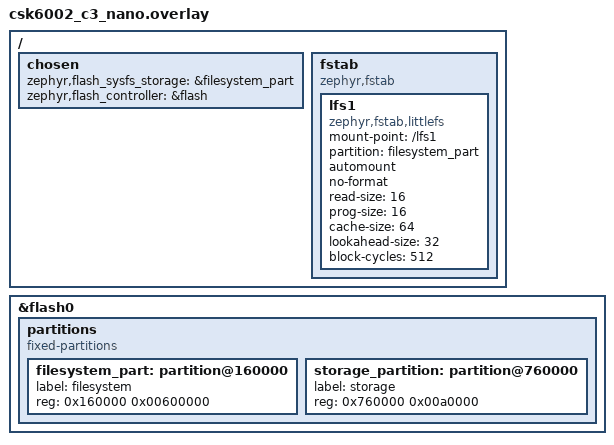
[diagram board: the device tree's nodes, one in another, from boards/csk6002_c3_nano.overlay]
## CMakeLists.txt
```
cmake_minimum_required(VERSION 3.20.0)
# Copyright (c) 2018 Nordic Semiconductor ASA
# Copyright (c) 2019 Linaro Limited
#
# SPDX-License-Identifier: Apache-2.0
#

if("${BOARD}" STREQUAL "csk6002_c3_nano")
  set(BUILD_DSP_FIRMWARE ON)
  find_package(Zephyr REQUIRED HINTS $ENV{ZEPHYR_BASE})
  message(INFO " ${BOARD} compile as Master in this sample")
  target_sources(app PRIVATE src/main.c)
  add_subdirectory(./src)

else("${BOARD}" STREQUAL "ls_adsp_csk6")
  set(BUILD_DSP_FIRMWARE ON)
endif()


if(BUILD_DSP_FIRMWARE)

  set(REMOTE_ZEPHYR_DIR ${CMAKE_CURRENT_BINARY_DIR}/openamp_remote-prefix/src/openamp_remote-build/zephyr)

  if("${BOARD}" STREQUAL "csk6002_c3_nano")
    set(BOARD_REMOTE "ls_adsp_csk6")
  else()
    message(FATAL_ERROR "${BOARD} was not supported for this sample")
  endif()

  project(openamp)

  enable_language(C ASM)

  #target_sources(app PRIVATE src/load_fw.c src/mem_image_store.c src/platform_info.c src/zynqmp_csk6001_rproc_example.c )

  include(ExternalProject)

  set(ENV{XCC_USE_CLANG} "1")
  set(ENV{ZEPHYR_TOOLCHAIN_VARIANT} "xcc")

  ExternalProject_Add(
    openamp_remote
    SOURCE_DIR ${APPLICATION_SOURCE_DIR}/remote
    INSTALL_COMMAND ""      # This particular build system has no install command
    CMAKE_CACHE_ARGS -DBOARD:STRING=${BOARD_REMOTE}
    BUILD_BYPRODUCTS "${REMOTE_ZEPHYR_DIR}/${KERNEL_BIN_NAME}"
    # NB: Do we need to pass on more CMake variables?
    BUILD_ALWAYS True
  )

  unset(ENV{XCC_USE_CLANG})
  unset(ENV{ZEPHYR_TOOLCHAIN_VARIANT})
  # target_include_directories(app PRIVATE ${CMAKE_CURRENT_SOURCE_DIR} ./src) 

endif()

target_include_directories(app PRIVATE ${CMAKE_CURRENT_SOURCE_DIR} ./src) 
```

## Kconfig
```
# Private config options for load sencond core firmware app

# SPDX-License-Identifier: Apache-2.0

# Workaround for not being able to have commas in macro arguments

menu "Load Second Core Options"
	depends on SOC_CSK6001

choice
	prompt "The second core load method selection"
	default SECOND_CORE_LOAD_BY_LITTLEFS

config SECOND_CORE_LOAD_BY_FLASH_ELF
	bool "load the second core fw by *.elf file store at flash area"

config SECOND_CORE_IMAGE_ELF_ADDR
	depends on SECOND_CORE_LOAD_BY_FLASH_ELF
	hex "Address the second core firmware storage in flash,the file must be elf format"
	default 0x18200000
	help
	  This is the address the second core image storage in flash. Additionally
	  The data at this address will be load to run at the boot address.

config SECOND_CORE_LOAD_BY_FLASH_BINARY
	bool "load the second core fw by *.bin file store at flash area"

config SECOND_CORE_IMAGE_BINARY_ADDR
	depends on SECOND_CORE_LOAD_BY_FLASH_BINARY
	hex "Address the second core firmware storage in flash,the file must be binary format"
	default 0x18200000
	help
	  This is the address the second core image storage in flash. Additionally
	  The data at this address will be load to run at the boot address.

config SECOND_CORE_IMAGE_BINARY_SIZE
	depends on SECOND_CORE_LOAD_BY_FLASH_BINARY
	hex "The binary fw size of second core firmware storage in flash,the file must be binary format"
	default 0x100000
	help
	  This is the address the second core image storage in flash. Additionally
	  The data at this address will be load to run at the boot address.

config SECOND_CORE_LOAD_BY_LITTLEFS
	bool "load the second core fw by littleFS"
	imply DISK_DRIVER_FLASH
	imply FILE_SYSTEM
	imply FILE_SYSTEM_LITTLEFS

config SECOND_CORE_IMAGE_NAME
	depends on SECOND_CORE_LOAD_BY_LITTLEFS
	default "zephyr.bin"
	string "Binary image name of second core's code"
	help
	  This points to the image file for the the binary code that will be
	  used by the second core.


config SECOND_CORE_LOAD_BY_FATFS
	bool "load the second core fw by fatfs"
	imply DISK_DRIVER_FLASH
	imply FILE_SYSTEM
	imply FAT_FILESYSTEM_ELM


config SECOND_CORE_IMAGE_NAME
	depends on SECOND_CORE_LOAD_BY_FATFS
	default "zephyr.bin"
	string "Binary image name of second core's code"
	help
	  This points to the image file for the the binary code that will be
	  used by the second core.

endchoice


config SECOND_CORE_BOOT_ADDRESS
	hex "Address the second core will boot at"
	default 0x60000000
	help
	  This is the address the second core will boot from. Additionally this
	  address is where we will copy the SECOND_IMAGE to. We default this to
	  the base of PSRAM.


endmenu

if DISK_DRIVER_FLASH

DT_CHOSEN_Z_FLASH_SYSFS_STORAGE := zephyr,flash_sysfs_storage
DT_CHOSEN_Z_FLASH_CONTROLLER := zephyr,flash_controller
DT_CHOSEN_Z_INN_FLASH := zephyr,flash


config DISK_FLASH_START
	default "$(dt_chosen_reg_addr_hex,$(DT_CHOSEN_Z_FLASH_SYSFS_STORAGE))"

config DISK_FLASH_DEV_NAME
	default "$(dt_chosen_label,$(DT_CHOSEN_Z_FLASH_CONTROLLER))"

config DISK_VOLUME_SIZE
	default "$(dt_chosen_reg_size_hex,$(DT_CHOSEN_Z_FLASH_SYSFS_STORAGE))"


config DISK_FLASH_MAX_RW_SIZE
	default 4096
	#default $(dt_node_int_prop_hex,$(DT_CHOSEN_Z_INN_FLASH),erase-block-size)

config DISK_FLASH_ERASE_ALIGNMENT
	default 0x1000
	#default "$(dt_node_int_prop_hex,$(DT_CHOSEN_Z_INN_FLASH),erase-block-size)"

config DISK_ERASE_BLOCK_SIZE
	default 0x1000
	#default "$(dt_node_int_prop_hex,$(DT_CHOSEN_Z_INN_FLASH),erase-block-size)"

#USB config
config MASS_STORAGE_DISK_NAME
	default "NAND" 


config FLASH_LOG_LEVEL
	default 4


		
endif #DISK_DRIVER_FLASH

config FLASH
	default y

config FLASH_MAP
	default y

config FLASH_PAGE_LAYOUT
	default y

source "Kconfig.zephyr"
```

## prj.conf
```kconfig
CONFIG_PRINTK=y
CONFIG_DEBUG=y
CONFIG_LOG=y
CONFIG_MAIN_STACK_SIZE=4096
CONFIG_HEAP_MEM_POOL_SIZE=8192

#openamp config
CONFIG_OPENAMP=y
CONFIG_OPENAMP_SLAVE=n
CONFIG_CACHE_MANAGEMENT=y
CONFIG_HAS_EXTERNAL_CACHE=y

#psram init 
CONFIG_MINIMAL_LIBC_RAND=y

#file system select
#CONFIG_SECOND_CORE_LOAD_BY_LITTLEFS=y
CONFIG_SECOND_CORE_LOAD_BY_FATFS=y
#CONFIG_SECOND_CORE_LOAD_BY_FLASH_ELF=y
#CONFIG_SECOND_CORE_LOAD_BY_FLASH_BINARY=y


#usb mass storage
CONFIG_USB_DEVICE_STACK=y
CONFIG_USB_DEVICE_PRODUCT="Zephyr DFU sample"
CONFIG_USB_MASS_STORAGE=y
CONFIG_MASS_STORAGE_STACK_SIZE=4096
CONFIG_SYSTEM_WORKQUEUE_STACK_SIZE=4096


CONFIG_USB_DRIVER_LOG_LEVEL_ERR=y
CONFIG_USB_DEVICE_LOG_LEVEL_ERR=y
CONFIG_USB_MASS_STORAGE_LOG_LEVEL_ERR=y
CONFIG_USB_DRIVER_LOG_LEVEL_ERR=y



#usb dfu
# CONFIG_USB_DFU_CLASS=y
# CONFIG_IMG_MANAGER=y
# CONFIG_IMG_BLOCK_BUF_SIZE=4096
# CONFIG_BOOTLOADER_MCUBOOT=y

#Fixd for WinUSB driver install.
CONFIG_USB_DEVICE_VID=0x2FE3
CONFIG_USB_DEVICE_PID=0x200
```

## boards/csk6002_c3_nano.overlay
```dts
/*
 * Copyright (c) 2021 listenai Intelligent Technology (anhui) Co., Ltd.
 *
 * SPDX-License-Identifier: Apache-2.0
 */
/delete-node/ &storage_partition;

/ {
	chosen {
		/*
		 * shared memory reserved for the inter-processor communication
		 */
		zephyr,flash_sysfs_storage = &filesystem_part;
		zephyr,flash_controller = &flash;
	};
	
	fstab {
		compatible = "zephyr,fstab";
		lfs1: lfs1 {
			compatible = "zephyr,fstab,littlefs";
			mount-point = "/lfs1";
			partition = <&filesystem_part>;
			automount ;
			no-format;
			read-size = <16>;
			prog-size = <16>;
			cache-size = <64>;
			lookahead-size = <32>;
			block-cycles = <512>;
		};
	};

};

 
&flash0 {
	partitions {
		compatible = "fixed-partitions";
		#address-cells = <1>;
		#size-cells = <1>;
		filesystem_part: partition@160000 {
			label = "filesystem";
			reg = <0x160000 0x00600000>;
		};
		/*
		 * Reserve the final 640 KiB for file system partition
		 */
		storage_partition: partition@760000 {
			label = "storage";
			reg = <0x760000 0x00a0000>;
		};
	};
};
```

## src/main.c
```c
/*
 *
 * SPDX-License-Identifier: Apache-2.0
 */

#include <zephyr.h>
#include <device.h>
#include <fs/fs.h>
#if defined(CONFIG_SECOND_CORE_LOAD_BY_LITTLEFS)
#include <fs/littlefs.h>
#include <storage/flash_map.h>
#include <usb/usb_device.h>
#elif defined(CONFIG_SECOND_CORE_LOAD_BY_FATFS)
#include <ff.h>
#include <usb/usb_device.h>
#endif

#include <drivers/ipm.h>
#include <sys/printk.h>
#include <stdio.h>
#include <stdlib.h>
#include <string.h>
#include <init.h>

#include <openamp/open_amp.h>
#include <metal/device.h>
#include <remote_core_ctrl.h>
#include <hal/PSRAMManager.h>
#include <hal/ClockManager.h>
#include <hal/SysManager.h>

#if defined(CONFIG_SECOND_CORE_LOAD_BY_LITTLEFS) || defined(CONFIG_SECOND_CORE_LOAD_BY_FATFS)

#if defined(CONFIG_SECOND_CORE_LOAD_BY_LITTLEFS)
/* Matches LFS_NAME_MAX */
#define MAX_PATH_LEN 255
#define PARTITION_NODE DT_NODELABEL(lfs1)
#if DT_NODE_EXISTS(PARTITION_NODE)
FS_FSTAB_DECLARE_ENTRY(PARTITION_NODE);
struct fs_mount_t *p_g_fs_mount = &FS_FSTAB_ENTRY(PARTITION_NODE);
#else /* PARTITION_NODE */
#error "Please declare the region of the file system first"
#endif /* PARTITION_NODE */
#elif defined(CONFIG_SECOND_CORE_LOAD_BY_FATFS)
#define FS_MOUNT_POINT "/NAND:"
struct fs_mount_t *p_g_fs_mount = NULL;
static struct fs_mount_t s_fs_mount;
static FATFS s_fat_fs;

#endif

static void fssys_show(struct fs_mount_t *mp)
{
	struct fs_statvfs sbuf;
	int rc;

	rc = fs_statvfs(mp->mnt_point, &sbuf);
	if (rc < 0) {
		printk("FAIL: statvfs: %d\n", rc);
		goto out;
	}

	printk("%s: bsize = %lu ; frsize = %lu ;"
	       " blocks = %lu ; bfree = %lu\n",
	       mp->mnt_point, sbuf.f_bsize, sbuf.f_frsize, sbuf.f_blocks, sbuf.f_bfree);

	struct fs_dir_t dir;

	fs_dir_t_init(&dir);

	rc = fs_opendir(&dir, mp->mnt_point);
	printk("%s opendir: %d\n", mp->mnt_point, rc);

	while (rc >= 0) {
		struct fs_dirent ent = { 0 };

		rc = fs_readdir(&dir, &ent);
		if (rc < 0) {
			break;
		}
		if (ent.name[0] == 0) {
			printk("End of files\n");
			break;
		}
		printk("  %c %zu %s\n", (ent.type == FS_DIR_ENTRY_FILE) ? 'F' : 'D', ent.size,
		       ent.name);
	}

	(void)fs_closedir(&dir);
	printk("%s closedir\n", mp->mnt_point);
out:
	return;
}

static int fs_init(void)
{
	struct fs_mount_t *mp;

#if defined(CONFIG_SECOND_CORE_LOAD_BY_LITTLEFS)
	mp = p_g_fs_mount;
	/* Do not mount if auto-mount has been enabled */
#if !DT_NODE_EXISTS(PARTITION_NODE) ||                                                             \
	!(FSTAB_ENTRY_DT_MOUNT_FLAGS(PARTITION_NODE) & FS_MOUNT_FLAG_AUTOMOUNT)

	int rc = fs_mount(mp);
	if (rc < 0) {
		printk("FAIL: mount id %" PRIuPTR " at %s: %d\n", (uintptr_t)mp->storage_dev,
		       mp->mnt_point, rc);
		return rc;
	}
	printk("%s mount: %d\n", mp->mnt_point, rc);
#else
	printk("%s automounted\n", mp->mnt_point);
#endif

#elif defined(CONFIG_SECOND_CORE_LOAD_BY_FATFS)
	if (p_g_fs_mount != NULL) {
		printk("The mount point<%s> busy!\n", p_g_fs_mount->mnt_point);
		return -1;
	}
	p_g_fs_mount = &s_fs_mount;
	mp = p_g_fs_mount;
	memset(mp, 0, sizeof(struct fs_mount_t));
	mp->type = FS_FATFS;
	mp->flags |= FS_MOUNT_FLAG_NO_FORMAT;
	mp->fs_data = &s_fat_fs;
	mp->mnt_point = FS_MOUNT_POINT;
	int rc = fs_mount(mp);
	if (rc < 0) {
		printk("FAIL: mount id %" PRIuPTR " at %s: %d\n", (uintptr_t)mp->storage_dev,
		       mp->mnt_point, rc);
		return rc;
	}
	printk("%s mount: %d\n", mp->mnt_point, rc);
#endif
	fssys_show(mp);

	return 0;
}
#endif

#if 0
void remote_runing_tester(int restartNumver)
{
	struct remoteproc *rproc = NULL;
	uint32_t testcnt = 0;
	uint32_t wait_ms = 0;
	int iret;

	rproc = remote_core_create(2);
	if (rproc == NULL) {
		LPRINTF("[%s %d]remote_core_create failed!\n", __FUNCTION__, __LINE__);
		return;
	}
	LPRINTF("Step1: Create rproc success!\n");

	iret = remote_core_loadFw(rproc);
	if (0 != iret) {
		LPRINTF("[%s %d]remote_core_loadFw failed!\n", __FUNCTION__, __LINE__);
		return;
	}
	LPRINTF("Step2: load second core firmware success!\n");

	for (testcnt = 0; testcnt < restartNumver; testcnt++) {
		LPRINTF("----tester loop cnt =%d---------\n", testcnt);
		if (testcnt > 0) {
			iret = remote_core_config(rproc, NULL);
			if (0 != iret) {
				LPRINTF("[%s %d]remote_core_start failed!\n", __FUNCTION__,
					__LINE__);
				return;
			}
			LPRINTF("Step3: reconfig second core success!\n");
		} else {
			LPRINTF("Step3: first jump config second core config success!\n");
		}
		k_msleep(200);
		iret = remote_core_start(rproc);
		if (0 != iret) {
			LPRINTF("[%s %d]remote_core_start failed!\n", __FUNCTION__, __LINE__);
			return;
		}
		LPRINTF("Step4: start second core success!\n");
		for (wait_ms = 10; wait_ms > 0; wait_ms--) {
			LPRINTF("[Master]Ctrl remote core goto stop wait (%d) millisecond...\n",
				wait_ms * 100);
			k_msleep(100);
		}
		iret = remote_core_stop(rproc);
		if (0 != iret) {
			LPRINTF("[%s %d]remote_core_stop failed!\n", __FUNCTION__, __LINE__);
			return;
		}
		LPRINTF("Step5: stop second core success!\n");
		//check cp stop state
		k_msleep(300);
		iret = remote_core_shutdown(rproc);
		if (0 != iret) {
			LPRINTF("[%s %d]remote_core_shutdown failed!\n", __FUNCTION__, __LINE__);
			return;
		}
		LPRINTF("Step6: shutdown second core success!\n");
	}
	iret = remote_core_remove(rproc);
	if (0 != iret) {
		LPRINTF("[%s %d]remote_core_remove failed!\n", __FUNCTION__, __LINE__);
		return;
	}
	LPRINTF("Step7: remove second core success!\n");
	LPRINTF("======The test success==========\n");
}
#else
void remote_runing_tester(int restartNumver)
{
	struct remoteproc *rproc = NULL;
	uint32_t wait_ms = 0;
	int iret;

	rproc = remote_core_create(2);
	if (rproc == NULL) {
		LPRINTF("[%s %d]remote_core_create failed!\n", __FUNCTION__, __LINE__);
		return;
	}
	LPRINTF("Step1: Create rproc success!\n");

	iret = remote_core_loadFw(rproc);
	if (0 != iret) {
		LPRINTF("[%s %d]remote_core_loadFw failed!\n", __FUNCTION__, __LINE__);
		return;
	}
	LPRINTF("Step2: load second core firmware success!\n");

	LPRINTF("Step3: first jump config second core config success!\n");

	k_msleep(200);
	iret = remote_core_start(rproc);
	if (0 != iret) {
		LPRINTF("[%s %d]remote_core_start failed!\n", __FUNCTION__, __LINE__);
		return;
	}
	LPRINTF("Step4: start second core success!\n");
	
	for (wait_ms = 10; wait_ms > 0; wait_ms--) {
		LPRINTF("[Master]Ctrl remote core goto stop wait (%d) millisecond...\n",
			wait_ms * 100);
		k_msleep(100);
	}
	
}
#endif

void main(void)
{
	int status = 0;
	int ret;
	struct metal_init_params metal_params = METAL_INIT_DEFAULTS;

	metal_params.log_level = METAL_LOG_DEBUG;
	status = metal_init(&metal_params);
	if (status != 0) {
		printk("metal_init: failed - error code %d\n", status);
		return;
	}
//file system init
#if defined(CONFIG_SECOND_CORE_LOAD_BY_LITTLEFS) || defined(CONFIG_SECOND_CORE_LOAD_BY_FATFS)
	fs_init();
	ret = usb_enable(NULL);
	if (ret != 0) {
		printk("Failed to enable USB");
		return;
	}
#endif
	
	remote_runing_tester(1);

	while (1) {
		k_msleep(1000);
	}
}

static int psram_init(const struct device *unused)
{
	ARG_UNUSED(unused);
	PSRAM_Initialize();

    // Enable CP clock
    __HAL_CRM_CP_CLK_ENABLE();
    // Disable NPU clock
    __HAL_CRM_NPU_CLK_ENABLE();

    if (__HAL_SYS_IS_CP_RESET()){
        __HAL_SYS_CP_RELEASE();
    }

    if (__HAL_SYS_NPU_IS_RESET()){
        __HAL_SYS_NPU_RELEASE();
    }
	return 0;
}

SYS_INIT(psram_init, PRE_KERNEL_2, 0);
```
